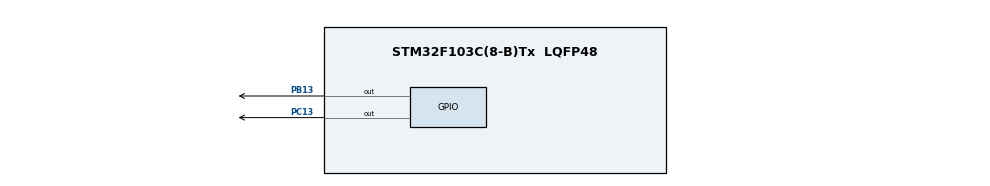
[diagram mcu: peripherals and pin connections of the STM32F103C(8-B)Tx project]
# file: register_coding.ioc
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Mcu.Family=STM32F1
Mcu.Name=STM32F103C(8-B)Tx
Mcu.Package=LQFP48
NVIC.PriorityGroup=NVIC_PRIORITYGROUP_4
PA13.Mode=Serial_Wire
PA13.Signal=SYS_JTMS-SWDIO
PA14.Mode=Serial_Wire
PA14.Signal=SYS_JTCK-SWCLK
PB13.Signal=GPIO_Output
PC13-TAMPER-RTC.Signal=GPIO_Output
PD0-OSC_IN.Mode=HSE-External-Oscillator
PD0-OSC_IN.Signal=RCC_OSC_IN
PD1-OSC_OUT.Mode=HSE-External-Oscillator
PD1-OSC_OUT.Signal=RCC_OSC_OUT
ProjectManager.HeapSize=0x200
ProjectManager.StackSize=0x400
ProjectManager.TargetToolchain=STM32CubeIDE
RCC.AHBFreq_Value=64000000
RCC.APB1CLKDivider=RCC_HCLK_DIV2
RCC.APB1Freq_Value=32000000
RCC.APB1TimFreq_Value=64000000
RCC.APB2Freq_Value=64000000
RCC.APB2TimFreq_Value=64000000
RCC.HCLKFreq_Value=64000000
RCC.HSEDivPLL=RCC_HSE_PREDIV_DIV2
RCC.PLLMUL=RCC_PLL_MUL16
RCC.PLLSourceVirtual=RCC_PLLSOURCE_HSE
RCC.SYSCLKFreq_VALUE=64000000
RCC.SYSCLKSource=RCC_SYSCLKSOURCE_PLLCLK
RCC.USBFreq_Value=64000000
board=custom

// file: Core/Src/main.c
/* USER CODE BEGIN Header */
/**
  ******************************************************************************
  * @file           : main.c
  * @brief          : Main program body
  ******************************************************************************
  * @attention
  *
  * <h2><center>&copy; Copyright (c) 2020 STMicroelectronics.
  * All rights reserved.</center></h2>
  *
  * This software component is licensed by ST under BSD 3-Clause license,
  * the "License"; You may not use this file except in compliance with the
  * License. You may obtain a copy of the License at:
  *                        opensource.org/licenses/BSD-3-Clause
  *
  ******************************************************************************
  */
/* USER CODE END Header */

#include "main.h"

void SystemClock_Config(void);
static void MX_GPIO_Init(void);

/* USER CODE BEGIN 0 */
//#define LED2_PIN                           LL_GPIO_PIN_5
//#define LED2_GPIO_PORT                     GPIOA
//#define LED2_GPIO_CLK_ENABLE()             LL_APB2_GRP1_EnableClock(LL_APB2_GRP1_PERIPH_GPIOA)
/* USER CODE END 0 */

int main(void)
{

  /* MCU Configuration--------------------------------------------------------*/

  /* Reset of all peripherals, Initializes the Flash interface and the Systick. */

  LL_APB2_GRP1_EnableClock(LL_APB2_GRP1_PERIPH_AFIO);
  LL_APB1_GRP1_EnableClock(LL_APB1_GRP1_PERIPH_PWR);

  NVIC_SetPriorityGrouping(NVIC_PRIORITYGROUP_4);

  /* System interrupt init*/

  /** NOJTAG: JTAG-DP Disabled and SW-DP Enabled
  */
  LL_GPIO_AF_Remap_SWJ_NOJTAG();

  /* Configure the system clock */
  SystemClock_Config();

  /* Initialize all configured peripherals */
  MX_GPIO_Init();

  /* Infinite loop */
  while (1)
  {

    /* USER CODE BEGIN 3 */

	 GPIOC->ODR |= GPIO_ODR_ODR13;
	 LL_mDelay(500);

	 GPIOC->ODR &= ~GPIO_ODR_ODR13;
	 LL_mDelay(500);
  }
  /* USER CODE END 3 */
}

void SystemClock_Config(void)
{

  FLASH->ACR = (FLASH->ACR) | LL_FLASH_LATENCY_2;
  RCC->CR |= RCC_CR_HSEON;
  RCC->CFGR |= (RCC_CFGR_PLLSRC | 0x00000000U);// Setup PLL source without prescale
  RCC->CFGR |=	RCC_CFGR_PLLMULL9;             // Setup PLL multiplication factor
  RCC->CR |= RCC_CR_PLLON;
  RCC->CFGR |= RCC_CFGR_SW_PLL;
  RCC->CFGR |= RCC_CFGR_PPRE1_DIV2 | RCC_CFGR_PPRE2_DIV1;
  LL_Init1msTick(72000000);
  SysTick->CTRL |= LL_SYSTICK_CLKSOURCE_HCLK;
  LL_SetSystemCoreClock(72000000);
}

static void MX_GPIO_Init(void)
{
  /* GPIO Ports Clock Enable */
  RCC->APB2ENR |= RCC_APB2ENR_IOPCEN;
  GPIOC->CRH |= GPIO_CRH_MODE13_0;
}

void Error_Handler(void)
{
}

/************************ (C) COPYRIGHT STMicroelectronics *****END OF FILE****/
